# STM32H7RSxx register map
File version: 0.2
CPU: CM7 r0p1, little endian, MPU, FPU, 4 interrupt priority bits
Registers are 32-bit, read-write, reset 0x0 unless marked. A register's access mark holds for its fields unless they carry their own. Offsets are from the block's base; [hi:lo] are bit positions; <NAME> marks a mode.

## OTG_HS (part 1 of 3) — OTG register block
Base 0x40040000
Same registers: OTG_FS 0x40080000
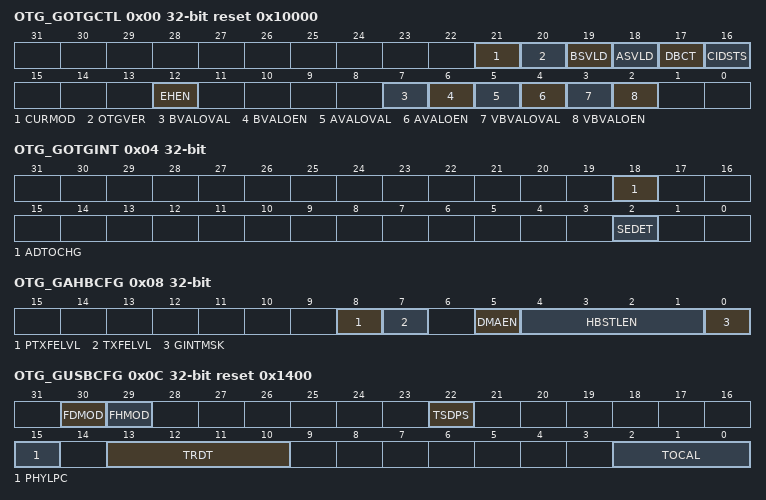
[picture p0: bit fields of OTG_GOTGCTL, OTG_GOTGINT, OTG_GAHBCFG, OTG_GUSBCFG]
0x00 OTG_GOTGCTL access per field reset 0x10000 — OTG control and status register
  [21] CURMOD ro — Current mode of operation Indicates the current mode (host or device).
    0=Device mode; 1=Host mode
  [20] OTGVER rw — OTG version Selects the OTG revision.
    0=OTG Version 1.3. OTG1.3 is obsolete for new product development.; 1=OTG Version 2.0. In this version the core supports only data line pulsing for SRP.
  [19] BSVLD ro — B-session valid Indicates the device mode transceiver status. In OTG mode, the user can use this bit to determine if the device is connected or disconnected. Note: Only accessible in device mode.
    0=B-session is not valid; 1=B-session is valid
  [18] ASVLD ro — A-session valid Indicates the host mode transceiver status. Note: Only accessible in host mode.
    0=A-session is not valid; 1=A-session is valid
  [17] DBCT ro — Long/short debounce time Indicates the debounce time of a detected connection. Note: Only accessible in host mode.
    0=Long debounce time, used for physical connections (100 ms + 2.5 �s); 1=Short debounce time, used for soft connections (2.5 �s)
  [16] CIDSTS ro — Connector ID status Indicates the connector ID status on a connect event. Note: Accessible in both device and host modes.
    0=The OTG_HS controller is in A-device mode; 1=The OTG_HS controller is in B-device mode
  [12] EHEN rw — Embedded host enable It is used to select between OTG A device state machine and embedded host state machine.
    0=OTG A device state machine is selected; 1=Embedded host state machine is selected
  [7] BVALOVAL rw — B-peripheral session valid override value. This bit is used to set override value for Bvalid signal when BVALOEN bit is set. Note: Only accessible in device mode.
    0=Bvalid value is '0' when BVALOEN = 1; 1=Bvalid value is '1' when BVALOEN = 1
  [6] BVALOEN rw — B-peripheral session valid override enable. This bit is used to enable/disable the software to override the Bvalid signal using the BVALOVAL bit. 1 Internally Bvalid received from the PHY is overridden with BVALOVAL bit value Note: Only accessible in device mode.
    0=Override is disabled and Bvalid signal from the respective PHY selected is used internally by the core
  [5] AVALOVAL rw — A-peripheral session valid override value. This bit is used to set override value for Avalid signal when AVALOEN bit is set. Note: Only accessible in host mode.
    0=Avalid value is '0' when AVALOEN = 1; 1=Avalid value is '1' when AVALOEN = 1
  [4] AVALOEN rw — A-peripheral session valid override enable. This bit is used to enable/disable the software to override the Avalid signal using the AVALOVAL bit. Note: Only accessible in host mode.
    0=Override is disabled and Avalid signal from the respective PHY selected is used internally by the core; 1=Internally Avalid received from the PHY is overridden with AVALOVAL bit value
  [3] VBVALOVAL rw — V<sub>BUS</sub> valid override value. This bit is used to set override value for vbusvalid signal when VBVALOEN bit is set. Note: Only accessible in host mode.
    0=vbusvalid value is '0' when VBVALOEN = 1; 1=vbusvalid value is '1' when VBVALOEN = 1
  [2] VBVALOEN rw — V<sub>BUS</sub> valid override enable. This bit is used to enable/disable the software to override the vbusvalid signal using the VBVALOVAL bit. Note: Only accessible in host mode.
    0=Override is disabled and vbusvalid signal from the respective PHY selected is used internally by the core; 1=Internally vbusvalid received from the PHY is overridden with VBVALOVAL bit value
0x04 OTG_GOTGINT — OTG interrupt register
  [18] ADTOCHG — A-device timeout change The core sets this bit to indicate that the A-device has timed out while waiting for the B-device to connect. Note: Accessible in both device and host modes.
  [2] SEDET — Session end detected The core sets this bit to indicate that the level of the voltage on V<sub>BUS</sub> is no longer valid for a B-Peripheral session when V<sub>BUS</sub> < 0.8 V. Note: Accessible in both device and host modes.
0x08 OTG_GAHBCFG — OTG AHB configuration register
  [8] PTXFELVL — Periodic Tx FIFO empty level Indicates when the periodic Tx FIFO empty interrupt bit in the OTG_GINTSTS register (PTXFE bit in OTG_GINTSTS) is triggered. Note: Only accessible in host mode.
    0=PTXFE (in OTG_GINTSTS) interrupt indicates that the Periodic Tx FIFO is half empty; 1=PTXFE (in OTG_GINTSTS) interrupt indicates that the Periodic Tx FIFO is completely empty
  [7] TXFELVL — Tx FIFO empty level This bit indicates when IN endpoint Transmit FIFO empty interrupt (TXFE in OTG_DIEPINTx) is triggered: This bit indicates when the nonperiodic Tx FIFO empty interrupt (NPTXFE bit in OTG_GINTSTS) is triggered:
    0=B_0x0_DEVICE_MODE (The TXFE (in OTG_DIEPINTx) interrupt indicates that the IN endpoint Tx FIFO is half empty); 1=B_0x1_DEVICE_MODE (The TXFE (in OTG_DIEPINTx) interrupt indicates that the IN endpoint Tx FIFO is completely empty); 0=B_0x0_HOST_MODE (The NPTXFE (in OTG_GINTSTS) interrupt indicates that the nonperiodic Tx FIFO is half empty); 1=B_0x1_HOST_MODE (The NPTXFE (in OTG_GINTSTS) interrupt indicates that the nonperiodic Tx FIFO is completely empty)
  [5] DMAEN — DMA enabled
    0=The core operates in slave mode; 1=The core operates in DMA mode
  [4:1] HBSTLEN — Burst length/type 0000 Single: Bus transactions use single 32 bit accesses (not recommended) 0001 INCR: Bus transactions use unspecified length accesses (not recommended, uses the INCR AHB bus command) 0011 INCR4: Bus transactions target 4x 32 bit accesses 0101 INCR8: Bus transactions target 8x 32 bit accesses 0111 INCR16: Bus transactions based on 16x 32 bit accesses Others: Reserved
  [0] GINTMSK — Global interrupt mask The application uses this bit to mask or unmask the interrupt line assertion to itself. Irrespective of this bit’s setting, the interrupt status registers are updated by the core. Note: Accessible in both device and host modes.
    0=Mask the interrupt assertion to the application; 1=Unmask the interrupt assertion to the application
0x0C OTG_GUSBCFG reset 0x1400 — OTG USB configuration register
  [30] FDMOD — Force device mode Writing a 1 to this bit, forces the core to device mode irrespective of the OTG_ID input pin. After setting the force bit, the application must wait at least 25 ms before the change takes effect. Note: Accessible in both device and host modes.
    0=Normal mode; 1=Force device mode
  [29] FHMOD — Force host mode Writing a 1 to this bit, forces the core to host mode irrespective of the OTG_ID input pin. After setting the force bit, the application must wait at least 25 ms before the change takes effect. Note: Accessible in both device and host modes.
    0=Normal mode; 1=Force host mode
  [22] TSDPS — TermSel DLine pulsing selection This bit selects utmi_termselect to drive the data line pulse during SRP (session request protocol).
    0=Data line pulsing using utmi_txvalid (default); 1=Data line pulsing using utmi_termsel
  [15] PHYLPC — PHY Low-power clock select This bit selects either 480 MHz or 48 MHz (low-power) PHY mode. In FS and LS modes, the PHY can usually operate on a 48 MHz clock to save power. In 480 MHz mode, the UTMI interface operates at either 60 or 30 MHz, depending on whether the 8- or 16-bit data width is selected. In 48 MHz mode, the UTMI interface operates at 48 MHz in FS and LS modes.
    0=480 MHz internal PLL clock; 1=48 MHz external clock
  [13:10] TRDT — USB turnaround time These bits allows to set the turnaround time in PHY clocks. They must be configured according to Table 683: TRDT values, depending on the application AHB frequency. Higher TRDT values allow stretching the USB response time to IN tokens in order to compensate for longer AHB read access latency to the data FIFO. Note: Only accessible in device mode.
  [2:0] TOCAL — FS timeout calibration The number of PHY clocks that the application programs in this field is added to the full-speed interpacket timeout duration in the core to account for any additional delays introduced by the PHY. This can be required, because the delay introduced by the PHY in generating the line state condition can vary from one PHY to another. The USB standard timeout value for full-speed operation is 16 to 18 (inclusive) bit times. The application must program this field based on the speed of enumeration. The number of bit times added per PHY clock is 0.25 bit times.
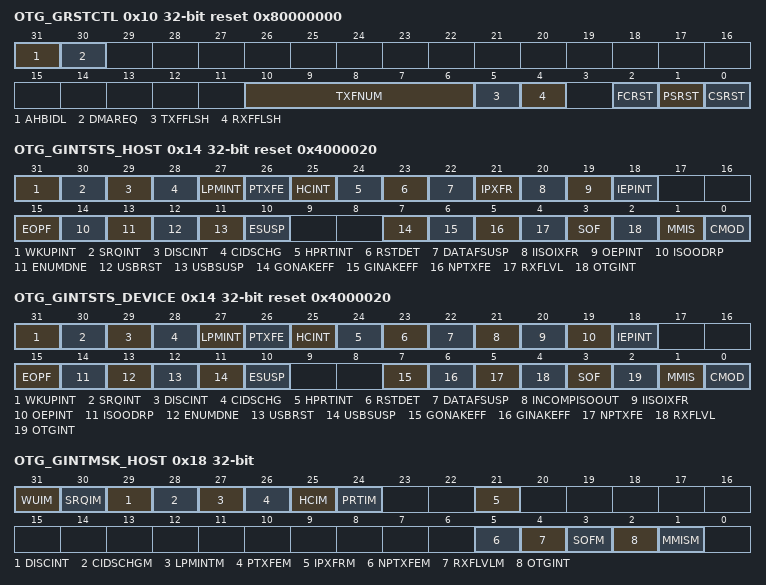
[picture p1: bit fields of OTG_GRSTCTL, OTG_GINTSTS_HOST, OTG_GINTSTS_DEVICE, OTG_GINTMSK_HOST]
0x10 OTG_GRSTCTL access per field reset 0x80000000 — OTG reset register
  [31] AHBIDL ro — AHB master idle Indicates that the AHB master state machine is in the Idle condition. Note: Accessible in both device and host modes.
  [30] DMAREQ ro — DMA request signal enabled This bit indicates that the DMA request is in progress. Used for debug.
  [10:6] TXFNUM rw — Tx FIFO number This is the FIFO number that must be flushed using the Tx FIFO Flush bit. This field must not be changed until the core clears the Tx FIFO Flush bit. ... Note: Accessible in both device and host modes.
    0=B_0x0_HOST_MODE (Non-periodic Tx FIFO flush); 1=B_0x1_HOST_MODE (Periodic Tx FIFO flush); 16=B_0x10_HOST_MODE (Flush all the transmit FIFOs); 0=B_0x0_DEVICE_MODE (Tx FIFO 0 flush); 1=B_0x1_DEVICE_MODE (Tx FIFO 1 flush); 2=B_0x2_DEVICE_MODE (Tx FIFO 2 flush); 15=B_0xF_DEVICE_MODE (Tx FIFO 15 flush); 16=B_0x10_DEVICE_MODE (Flush all the transmit FIFOs)
  [5] TXFFLSH rw — Tx FIFO flush This bit selectively flushes a single or all transmit FIFOs, but cannot do so if the core is in the midst of a transaction. The application must write this bit only after checking that the core is neither writing to the Tx FIFO nor reading from the Tx FIFO. Verify using these registers: Read—NAK Effective interrupt ensures the core is not reading from the FIFO Write—AHBIDL bit in OTG_GRSTCTL ensures the core is not writing anything to the FIFO. Flushing is normally recommended when FIFOs are reconfigured. FIFO flushing is also recommended during device endpoint disable. The application must wait until the core clears this bit before performing any operations. This bit takes eight clocks to clear, using the slower clock of phy_clk or hclk. Note: Accessible in both device and host modes.
  [4] RXFFLSH rw — Rx FIFO flush The application can flush the entire Rx FIFO using this bit, but must first ensure that the core is not in the middle of a transaction. The application must only write to this bit after checking that the core is neither reading from the Rx FIFO nor writing to the Rx FIFO. The application must wait until the bit is cleared before performing any other operations. This bit requires 8 clocks (slowest of PHY or AHB clock) to clear. Note: Accessible in both device and host modes.
  [2] FCRST rw — Host frame counter reset The application writes this bit to reset the (micro-)frame number counter inside the core. When the (micro-)frame counter is reset, the subsequent SOF sent out by the core has a frame number of 0. When application writes '1' to the bit, it might not be able to read back the value as it gets cleared by the core in a few clock cycles. Note: Only accessible in host mode.
  [1] PSRST rw — Partial soft reset Resets the internal state machines but keeps the enumeration info. Could be used to recover some specific PHY errors. Note: Accessible in both device and host modes.
  [0] CSRST rw — Core soft reset Resets the HCLK and PHY clock domains as follows: Clears the interrupts and all the CSR register bits except for the following bits: GATEHCLK bit in OTG_PCGCCTL STPPCLK bit in OTG_PCGCCTL FSLSPCS bits in OTG_HCFG DSPD bit in OTG_DCFG SDIS bit in OTG_DCTL OTG_GCCFG register All module state machines (except for the AHB slave unit) are reset to the Idle state, and all the transmit FIFOs and the receive FIFO are flushed. Any transactions on the AHB Master are terminated as soon as possible, after completing the last data phase of an AHB transfer. Any transactions on the USB are terminated immediately. The application can write to this bit any time it wants to reset the core. This is a self-clearing bit and the core clears this bit after all the necessary logic is reset in the core, which can take several clocks, depending on the current state of the core. Once this bit has been cleared, the software must wait at least 3 PHY clocks before accessing the PHY domain (synchronization delay). The software must also check that bit 31 in this register is set to 1 (AHB Master is Idle) before starting any operation. Typically, the software reset is used during software development and also when the user dynamically changes the PHY selection bits in the above listed USB configuration registers. When the user changes the PHY, the corresponding clock for the PHY is selected and used in the PHY domain. Once a new clock is selected, the PHY domain has to be reset for proper operation. Note: Accessible in both device and host modes.
0x14 OTG_GINTSTS_HOST access per field reset 0x4000020 — OTG core interrupt register
  [31] WKUPINT rw — Resume/remote wakeup detected interrupt Wakeup interrupt during suspend(L2) or LPM(L1) state. During suspend(L2): In device mode, this interrupt is asserted when a resume is detected on the USB. In host mode, this interrupt is asserted when a remote wakeup is detected on the USB. During LPM(L1): This interrupt is asserted for either host initiated resume or device initiated remote wakeup on USB. Note: Accessible in both device and host modes.
  [30] SRQINT rw — Session request/new session detected interrupt In host mode, this interrupt is asserted when a session request is detected from the device. In device mode, this interrupt is asserted when V<sub>BUS</sub> is in the valid range for a B-peripheral device. Accessible in both device and host modes.
  [29] DISCINT rw — Disconnect detected interrupt Asserted when a device disconnect is detected. Note: Only accessible in host mode.
  [28] CIDSCHG rw — Connector ID status change The core sets this bit when there is a change in connector ID status. Note: Accessible in both device and host modes.
  [27] LPMINT rw — LPM interrupt In device mode, this interrupt is asserted when the device receives an LPM transaction and responds with a non-ERRORed response. In host mode, this interrupt is asserted when the device responds to an LPM transaction with a non-ERRORed response or when the host core has completed LPM transactions for the programmed number of times (RETRYCNT bit in OTG_GLPMCFG). This field is valid only if the LPMEN bit in OTG_GLPMCFG is set to 1.
  [26] PTXFE ro — Periodic Tx FIFO empty Asserted when the periodic transmit FIFO is either half or completely empty and there is space for at least one entry to be written in the periodic request queue. The half or completely empty status is determined by the periodic Tx FIFO empty level bit in the OTG_GAHBCFG register (PTXFELVL bit in OTG_GAHBCFG). Note: Only accessible in host mode.
  [25] HCINT ro — Host channels interrupt The core sets this bit to indicate that an interrupt is pending on one of the channels of the core (in host mode). The application must read the OTG_HAINT register to determine the exact number of the channel on which the interrupt occurred, and then read the corresponding OTG_HCINTx register to determine the exact cause of the interrupt. The application must clear the appropriate status bit in the OTG_HCINTx register to clear this bit. Note: Only accessible in host mode.
  [24] HPRTINT ro — Host port interrupt The core sets this bit to indicate a change in port status of one of the OTG_HS controller ports in host mode. The application must read the OTG_HPRT register to determine the exact event that caused this interrupt. The application must clear the appropriate status bit in the OTG_HPRT register to clear this bit. Note: Only accessible in host mode.
  [23] RSTDET rw — Reset detected interrupt In device mode, this interrupt is asserted when a reset is detected on the USB in partial power-down mode when the device is in suspend. Note: Only accessible in device mode.
  [22] DATAFSUSP rw — Data fetch suspended This interrupt is valid only in DMA mode. This interrupt indicates that the core has stopped fetching data for IN endpoints due to the unavailability of TxFIFO space or request queue space. This interrupt is used by the application for an endpoint mismatch algorithm. For example, after detecting an endpoint mismatch, the application: Sets a global nonperiodic IN NAK handshake Disables IN endpoints Flushes the FIFO Determines the token sequence from the IN token sequence learning queue Re-enables the endpoints Clears the global nonperiodic IN NAK handshake If the global nonperiodic IN NAK is cleared, the core has not yet fetched data for the IN endpoint, and the IN token is received: the core generates an “IN token received when FIFO empty” interrupt. The OTG then sends a NAK response to the host. To avoid this scenario, the application can check the FetSusp interrupt in OTG_GINTSTS, which ensures that the FIFO is full before clearing a global NAK handshake. Alternatively, the application can mask the “IN token received when FIFO empty” interrupt when clearing a global IN NAK handshake.
  [21] IPXFR rw — Incomplete periodic transfer In host mode, the core sets this interrupt bit when there are incomplete periodic transactions still pending, which are scheduled for the current frame.
  [20] IISOIXFR rw — Incomplete isochronous IN transfer The core sets this interrupt to indicate that there is at least one isochronous IN endpoint on which the transfer is not completed in the current frame. This interrupt is asserted along with the End of periodic frame interrupt (EOPF) bit in this register. Note: Only accessible in device mode.
  [19] OEPINT ro — OUT endpoint interrupt The core sets this bit to indicate that an interrupt is pending on one of the OUT endpoints of the core (in device mode). The application must read the OTG_DAINT register to determine the exact number of the OUT endpoint on which the interrupt occurred, and then read the corresponding OTG_DOEPINTx register to determine the exact cause of the interrupt. The application must clear the appropriate status bit in the corresponding OTG_DOEPINTx register to clear this bit. Note: Only accessible in device mode.
  [18] IEPINT ro — IN endpoint interrupt The core sets this bit to indicate that an interrupt is pending on one of the IN endpoints of the core (in device mode). The application must read the OTG_DAINT register to determine the exact number of the IN endpoint on which the interrupt occurred, and then read the corresponding OTG_DIEPINTx register to determine the exact cause of the interrupt. The application must clear the appropriate status bit in the corresponding OTG_DIEPINTx register to clear this bit. Note: Only accessible in device mode.
  [15] EOPF rw — End of periodic frame interrupt Indicates that the period specified in the periodic frame interval field of the OTG_DCFG register (PFIVL bit in OTG_DCFG) has been reached in the current frame. Note: Only accessible in device mode.
  [14] ISOODRP rw — Isochronous OUT packet dropped interrupt The core sets this bit when it fails to write an isochronous OUT packet into the Rx FIFO because the Rx FIFO does not have enough space to accommodate a maximum size packet for the isochronous OUT endpoint. Note: Only accessible in device mode.
  [13] ENUMDNE rw — Enumeration done The core sets this bit to indicate that speed enumeration is complete. The application must read the OTG_DSTS register to obtain the enumerated speed. Note: Only accessible in device mode.
  [12] USBRST rw — USB reset The core sets this bit to indicate that a reset is detected on the USB. Note: Only accessible in device mode.
  [11] USBSUSP rw — USB suspend The core sets this bit to indicate that a suspend was detected on the USB. The core enters the suspended state when there is no activity on the data lines for an extended period of time. Note: Only accessible in device mode.
  [10] ESUSP rw — Early suspend The core sets this bit to indicate that an Idle state has been detected on the USB for 3 ms. Note: Only accessible in device mode.
  [7] GONAKEFF ro — Global OUT NAK effective Indicates that the Set global OUT NAK bit in the OTG_DCTL register (SGONAK bit in OTG_DCTL), set by the application, has taken effect in the core. This bit can be cleared by writing the Clear global OUT NAK bit in the OTG_DCTL register (CGONAK bit in OTG_DCTL). Note: Only accessible in device mode.
  [6] GINAKEFF ro — Global IN non-periodic NAK effective Indicates that the Set global non-periodic IN NAK bit in the OTG_DCTL register (SGINAK bit in OTG_DCTL), set by the application, has taken effect in the core. That is, the core has sampled the Global IN NAK bit set by the application. This bit can be cleared by clearing the Clear global non-periodic IN NAK bit in the OTG_DCTL register (CGINAK bit in OTG_DCTL). This interrupt does not necessarily mean that a NAK handshake is sent out on the USB. The STALL bit takes precedence over the NAK bit. Note: Only accessible in device mode.
  [5] NPTXFE ro — Non-periodic Tx FIFO empty This interrupt is asserted when the non-periodic Tx FIFO is either half or completely empty, and there is space for at least one entry to be written to the non-periodic transmit request queue. The half or completely empty status is determined by the non-periodic Tx FIFO empty level bit in the OTG_GAHBCFG register (TXFELVL bit in OTG_GAHBCFG). Note: Accessible in host mode only.
  [4] RXFLVL ro — Rx FIFO non-empty Indicates that there is at least one packet pending to be read from the Rx FIFO. Note: Accessible in both host and device modes.
  [3] SOF rw — Start of frame In host mode, the core sets this bit to indicate that an SOF (FS), or Keep-Alive (LS) is transmitted on the USB. The application must write a 1 to this bit to clear the interrupt. In device mode, in the core sets this bit to indicate that an SOF token has been received on the USB. The application can read the OTG_DSTS register to get the current frame number. This interrupt is seen only when the core is operating in FS. Note: This register may return '1' if read immediately after power on reset. If the register bit reads '1' immediately after power on reset it does not indicate that an SOF has been sent (in case of host mode) or SOF has been received (in case of device mode). The read value of this interrupt is valid only after a valid connection between host and device is established. If the bit is set after power on reset the application can clear the bit. Note: Accessible in both host and device modes.
  [2] OTGINT ro — OTG interrupt The core sets this bit to indicate an OTG protocol event. The application must read the OTG interrupt status (OTG_GOTGINT) register to determine the exact event that caused this interrupt. The application must clear the appropriate status bit in the OTG_GOTGINT register to clear this bit. Note: Accessible in both host and device modes.
  [1] MMIS rw — Mode mismatch interrupt The core sets this bit when the application is trying to access: A host mode register, when the core is operating in device mode A device mode register, when the core is operating in host mode The register access is completed on the AHB with an OKAY response, but is ignored by the core internally and does not affect the operation of the core. Note: Accessible in both host and device modes.
  [0] CMOD ro — Current mode of operation Indicates the current mode. Note: Accessible in both host and device modes.
    0=Device mode; 1=Host mode
0x14 OTG_GINTSTS_DEVICE access per field reset 0x4000020 (alternate view of OTG_GINTSTS_HOST) — OTG core interrupt register
  [31] WKUPINT rw — Resume/remote wakeup detected interrupt Wakeup interrupt during suspend(L2) or LPM(L1) state. During suspend(L2): In device mode, this interrupt is asserted when a resume is detected on the USB. In host mode, this interrupt is asserted when a remote wakeup is detected on the USB. During LPM(L1): This interrupt is asserted for either host initiated resume or device initiated remote wakeup on USB. Note: Accessible in both device and host modes.
  [30] SRQINT rw — Session request/new session detected interrupt In host mode, this interrupt is asserted when a session request is detected from the device. In device mode, this interrupt is asserted when V<sub>BUS</sub> is in the valid range for a B-peripheral device. Accessible in both device and host modes.
  [29] DISCINT rw — Disconnect detected interrupt Asserted when a device disconnect is detected. Note: Only accessible in host mode.
  [28] CIDSCHG rw — Connector ID status change The core sets this bit when there is a change in connector ID status. Note: Accessible in both device and host modes.
  [27] LPMINT rw — LPM interrupt In device mode, this interrupt is asserted when the device receives an LPM transaction and responds with a non-ERRORed response. In host mode, this interrupt is asserted when the device responds to an LPM transaction with a non-ERRORed response or when the host core has completed LPM transactions for the programmed number of times (RETRYCNT bit in OTG_GLPMCFG). This field is valid only if the LPMEN bit in OTG_GLPMCFG is set to 1.
  [26] PTXFE ro — Periodic Tx FIFO empty Asserted when the periodic transmit FIFO is either half or completely empty and there is space for at least one entry to be written in the periodic request queue. The half or completely empty status is determined by the periodic Tx FIFO empty level bit in the OTG_GAHBCFG register (PTXFELVL bit in OTG_GAHBCFG). Note: Only accessible in host mode.
  [25] HCINT ro — Host channels interrupt The core sets this bit to indicate that an interrupt is pending on one of the channels of the core (in host mode). The application must read the OTG_HAINT register to determine the exact number of the channel on which the interrupt occurred, and then read the corresponding OTG_HCINTx register to determine the exact cause of the interrupt. The application must clear the appropriate status bit in the OTG_HCINTx register to clear this bit. Note: Only accessible in host mode.
  [24] HPRTINT ro — Host port interrupt The core sets this bit to indicate a change in port status of one of the OTG_HS controller ports in host mode. The application must read the OTG_HPRT register to determine the exact event that caused this interrupt. The application must clear the appropriate status bit in the OTG_HPRT register to clear this bit. Note: Only accessible in host mode.
  [23] RSTDET rw — Reset detected interrupt In device mode, this interrupt is asserted when a reset is detected on the USB in partial power-down mode when the device is in suspend. Note: Only accessible in device mode.
  [22] DATAFSUSP rw — Data fetch suspended This interrupt is valid only in DMA mode. This interrupt indicates that the core has stopped fetching data for IN endpoints due to the unavailability of TxFIFO space or request queue space. This interrupt is used by the application for an endpoint mismatch algorithm. For example, after detecting an endpoint mismatch, the application: Sets a global nonperiodic IN NAK handshake Disables IN endpoints Flushes the FIFO Determines the token sequence from the IN token sequence learning queue Re-enables the endpoints Clears the global nonperiodic IN NAK handshake If the global nonperiodic IN NAK is cleared, the core has not yet fetched data for the IN endpoint, and the IN token is received: the core generates an “IN token received when FIFO empty” interrupt. The OTG then sends a NAK response to the host. To avoid this scenario, the application can check the FetSusp interrupt in OTG_GINTSTS, which ensures that the FIFO is full before clearing a global NAK handshake. Alternatively, the application can mask the “IN token received when FIFO empty” interrupt when clearing a global IN NAK handshake.
  [21] INCOMPISOOUT rw — Incomplete isochronous OUT transfer In device mode, the core sets this interrupt to indicate that there is at least one isochronous OUT endpoint on which the transfer is not completed in the current frame. This interrupt is asserted along with the End of periodic frame interrupt (EOPF) bit in this register.
  [20] IISOIXFR rw — Incomplete isochronous IN transfer The core sets this interrupt to indicate that there is at least one isochronous IN endpoint on which the transfer is not completed in the current frame. This interrupt is asserted along with the End of periodic frame interrupt (EOPF) bit in this register. Note: Only accessible in device mode.
  [19] OEPINT ro — OUT endpoint interrupt The core sets this bit to indicate that an interrupt is pending on one of the OUT endpoints of the core (in device mode). The application must read the OTG_DAINT register to determine the exact number of the OUT endpoint on which the interrupt occurred, and then read the corresponding OTG_DOEPINTx register to determine the exact cause of the interrupt. The application must clear the appropriate status bit in the corresponding OTG_DOEPINTx register to clear this bit. Note: Only accessible in device mode.
  [18] IEPINT ro — IN endpoint interrupt The core sets this bit to indicate that an interrupt is pending on one of the IN endpoints of the core (in device mode). The application must read the OTG_DAINT register to determine the exact number of the IN endpoint on which the interrupt occurred, and then read the corresponding OTG_DIEPINTx register to determine the exact cause of the interrupt. The application must clear the appropriate status bit in the corresponding OTG_DIEPINTx register to clear this bit. Note: Only accessible in device mode.
  [15] EOPF rw — End of periodic frame interrupt Indicates that the period specified in the periodic frame interval field of the OTG_DCFG register (PFIVL bit in OTG_DCFG) has been reached in the current frame. Note: Only accessible in device mode.
  [14] ISOODRP rw — Isochronous OUT packet dropped interrupt The core sets this bit when it fails to write an isochronous OUT packet into the Rx FIFO because the Rx FIFO does not have enough space to accommodate a maximum size packet for the isochronous OUT endpoint. Note: Only accessible in device mode.
  [13] ENUMDNE rw — Enumeration done The core sets this bit to indicate that speed enumeration is complete. The application must read the OTG_DSTS register to obtain the enumerated speed. Note: Only accessible in device mode.
  [12] USBRST rw — USB reset The core sets this bit to indicate that a reset is detected on the USB. Note: Only accessible in device mode.
  [11] USBSUSP rw — USB suspend The core sets this bit to indicate that a suspend was detected on the USB. The core enters the suspended state when there is no activity on the data lines for an extended period of time. Note: Only accessible in device mode.
  [10] ESUSP rw — Early suspend The core sets this bit to indicate that an Idle state has been detected on the USB for 3 ms. Note: Only accessible in device mode.
  [7] GONAKEFF ro — Global OUT NAK effective Indicates that the Set global OUT NAK bit in the OTG_DCTL register (SGONAK bit in OTG_DCTL), set by the application, has taken effect in the core. This bit can be cleared by writing the Clear global OUT NAK bit in the OTG_DCTL register (CGONAK bit in OTG_DCTL). Note: Only accessible in device mode.
  [6] GINAKEFF ro — Global IN non-periodic NAK effective Indicates that the Set global non-periodic IN NAK bit in the OTG_DCTL register (SGINAK bit in OTG_DCTL), set by the application, has taken effect in the core. That is, the core has sampled the Global IN NAK bit set by the application. This bit can be cleared by clearing the Clear global non-periodic IN NAK bit in the OTG_DCTL register (CGINAK bit in OTG_DCTL). This interrupt does not necessarily mean that a NAK handshake is sent out on the USB. The STALL bit takes precedence over the NAK bit. Note: Only accessible in device mode.
  [5] NPTXFE ro — Non-periodic Tx FIFO empty This interrupt is asserted when the non-periodic Tx FIFO is either half or completely empty, and there is space for at least one entry to be written to the non-periodic transmit request queue. The half or completely empty status is determined by the non-periodic Tx FIFO empty level bit in the OTG_GAHBCFG register (TXFELVL bit in OTG_GAHBCFG). Note: Accessible in host mode only.
  [4] RXFLVL ro — Rx FIFO non-empty Indicates that there is at least one packet pending to be read from the Rx FIFO. Note: Accessible in both host and device modes.
  [3] SOF rw — Start of frame In host mode, the core sets this bit to indicate that an SOF (FS), or Keep-Alive (LS) is transmitted on the USB. The application must write a 1 to this bit to clear the interrupt. In device mode, in the core sets this bit to indicate that an SOF token has been received on the USB. The application can read the OTG_DSTS register to get the current frame number. This interrupt is seen only when the core is operating in FS. Note: This register may return '1' if read immediately after power on reset. If the register bit reads '1' immediately after power on reset it does not indicate that an SOF has been sent (in case of host mode) or SOF has been received (in case of device mode). The read value of this interrupt is valid only after a valid connection between host and device is established. If the bit is set after power on reset the application can clear the bit. Note: Accessible in both host and device modes.
  [2] OTGINT ro — OTG interrupt The core sets this bit to indicate an OTG protocol event. The application must read the OTG interrupt status (OTG_GOTGINT) register to determine the exact event that caused this interrupt. The application must clear the appropriate status bit in the OTG_GOTGINT register to clear this bit. Note: Accessible in both host and device modes.
  [1] MMIS rw — Mode mismatch interrupt The core sets this bit when the application is trying to access: A host mode register, when the core is operating in device mode A device mode register, when the core is operating in host mode The register access is completed on the AHB with an OKAY response, but is ignored by the core internally and does not affect the operation of the core. Note: Accessible in both host and device modes.
  [0] CMOD ro — Current mode of operation Indicates the current mode. Note: Accessible in both host and device modes.
    0=Device mode; 1=Host mode
0x18 OTG_GINTMSK_HOST access per field — OTG interrupt mask register
  [all] fields
    0=Masked interrupt; 1=Unmasked interrupt
  [31] WUIM rw — Resume/remote wakeup detected interrupt mask
  [30] SRQIM rw — Session request/new session detected interrupt mask
  [29] DISCINT rw — Disconnect detected interrupt mask
  [28] CIDSCHGM rw — Connector ID status change mask
  [27] LPMINTM rw — LPM interrupt mask
  [26] PTXFEM rw — Periodic Tx FIFO empty mask
  [25] HCIM rw — Host channels interrupt mask
  [24] PRTIM ro — Host port interrupt mask
  [21] IPXFRM rw — Incomplete periodic transfer mask
  [5] NPTXFEM rw — Non-periodic Tx FIFO empty mask
  [4] RXFLVLM rw — Receive FIFO non-empty mask
  [3] SOFM rw — Start of frame mask
  [2] OTGINT rw — OTG interrupt mask
  [1] MMISM rw — Mode mismatch interrupt mask
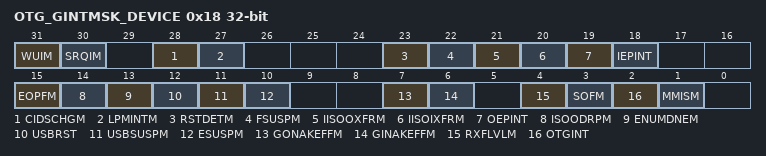
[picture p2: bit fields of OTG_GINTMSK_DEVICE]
0x18 OTG_GINTMSK_DEVICE (alternate view of OTG_GINTMSK_HOST) — OTG interrupt mask register
  [all] fields
    0=Masked interrupt; 1=Unmasked interrupt
  [31] WUIM — Resume/remote wakeup detected interrupt mask
  [30] SRQIM — Session request/new session detected interrupt mask
  [28] CIDSCHGM — Connector ID status change mask
  [27] LPMINTM — LPM interrupt mask
  [23] RSTDETM — Reset detected interrupt mask
  [22] FSUSPM — Data fetch suspended mask
  [21] IISOOXFRM — Incomplete isochronous OUT transfer mask
  [20] IISOIXFRM — Incomplete isochronous IN transfer mask
  [19] OEPINT — OUT endpoints interrupt mask
  [18] IEPINT — IN endpoints interrupt mask
  [15] EOPFM — End of periodic frame interrupt mask
  [14] ISOODRPM — Isochronous OUT packet dropped interrupt mask
  [13] ENUMDNEM — Enumeration done mask
  [12] USBRST — USB reset mask
  [11] USBSUSPM — USB suspend mask
  [10] ESUSPM — Early suspend mask
  [7] GONAKEFFM — Global OUT NAK effective mask
  [6] GINAKEFFM — Global non-periodic IN NAK effective mask
  [4] RXFLVLM — Receive FIFO non-empty mask
  [3] SOFM — Start of frame mask
  [2] OTGINT — OTG interrupt mask
  [1] MMISM — Mode mismatch interrupt mask
